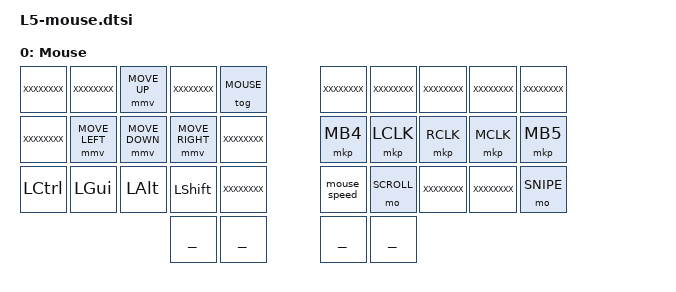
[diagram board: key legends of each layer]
/**
 *
 */

/ {
  keymap {
    compatible = "zmk,keymap";

	mouse_layer {
		label = "Mouse";
		bindings = <
//	╭───────────────┬───────────────┬───────────────┬───────────────┬───────────────╮   ╭───────────────┬───────────────┬───────────────┬───────────────┬───────────────╮
	XXXXXXXX        XXXXXXXX        &mmv MOVE_UP    XXXXXXXX        &tog MOUSE          XXXXXXXX        XXXXXXXX        XXXXXXXX        XXXXXXXX        XXXXXXXX
//	├───────────────┼───────────────┼───────────────┼───────────────┼───────────────┤   ├───────────────├───────────────┼───────────────┼───────────────┼───────────────┤
	XXXXXXXX        &mmv MOVE_LEFT  &mmv MOVE_DOWN  &mmv MOVE_RIGHT XXXXXXXX            &mkp MB4        &mkp LCLK       &mkp RCLK       &mkp MCLK       &mkp MB5
//	├───────────────┼───────────────┼───────────────┼───────────────┼───────────────┤   ├───────────────├───────────────┼───────────────┼───────────────┼───────────────┤
	&kp LCTRL       &kp LGUI        &kp LALT        &kp LSHFT       XXXXXXXX            &mouse_speed    &mo SCROLL      XXXXXXXX        XXXXXXXX        &mo SNIPE
//	╰───────────────┴───────────────┼───────────────┼───────────────┼───────────────┤   ├───────────────├───────────────┼───────────────┼───────────────┴───────────────╯
	       											________        ________           	________		________
//                                                  ╰───────────────┴───────────────╯   ╰───────────────┴───────────────╯
			>;
		};
	};
};
